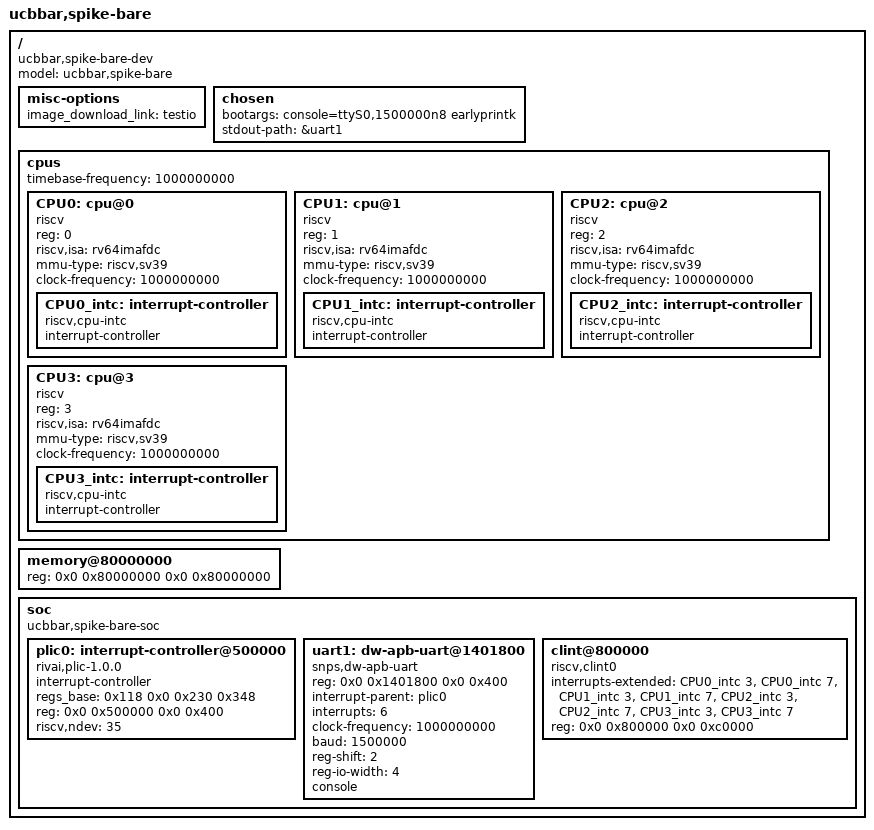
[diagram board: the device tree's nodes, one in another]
/dts-v1/;

/ {
  #address-cells = <2>;
  #size-cells = <2>;
  compatible = "ucbbar,spike-bare-dev";
  model = "ucbbar,spike-bare";
  misc-options {
       image_download_link = "testio";
  };
  chosen {
       bootargs = "console=ttyS0,1500000n8 earlyprintk";
       stdout-path = &uart1;
  };
  cpus {
    #address-cells = <1>;
    #size-cells = <0>;
    timebase-frequency = <1000000000>;
    CPU0: cpu@0 {
      device_type = "cpu";
      reg = <0>;
      status = "okay";
      compatible = "riscv";
      riscv,isa = "rv64imafdc";
      mmu-type = "riscv,sv39";
      clock-frequency = <1000000000>;
      CPU0_intc: interrupt-controller {
        #interrupt-cells = <1>;
        interrupt-controller;
        compatible = "riscv,cpu-intc";
      };
    };
    CPU1: cpu@1 {
      device_type = "cpu";
      reg = <1>;
      status = "okay";
      compatible = "riscv";
      riscv,isa = "rv64imafdc";
      mmu-type = "riscv,sv39";
      clock-frequency = <1000000000>;
      CPU1_intc: interrupt-controller {
        #interrupt-cells = <1>;
        interrupt-controller;
        compatible = "riscv,cpu-intc";
      };
    };
    CPU2: cpu@2 {
      device_type = "cpu";
      reg = <2>;
      status = "okay";
      compatible = "riscv";
      riscv,isa = "rv64imafdc";
      mmu-type = "riscv,sv39";
      clock-frequency = <1000000000>;
      CPU2_intc: interrupt-controller {
        #interrupt-cells = <1>;
        interrupt-controller;
        compatible = "riscv,cpu-intc";
      };
    };
    CPU3: cpu@3 {
      device_type = "cpu";
      reg = <3>;
      status = "okay";
      compatible = "riscv";
      riscv,isa = "rv64imafdc";
      mmu-type = "riscv,sv39";
      clock-frequency = <1000000000>;
      CPU3_intc: interrupt-controller {
        #interrupt-cells = <1>;
        interrupt-controller;
        compatible = "riscv,cpu-intc";
      };
    };
  };
  memory@80000000 {
    device_type = "memory";
    reg = <0x0 0x80000000 0x0 0x80000000>;
  };
  soc {
    #address-cells = <2>;
    #size-cells = <2>;
    compatible = "ucbbar,spike-bare-soc", "simple-bus";
    ranges;
    plic0: interrupt-controller@500000 {
      #interrupt-cells = <1>;
      compatible = "rivai,plic-1.0.0";
      interrupt-controller;
      regs_base = <0x118 0x0 0x230 0x348>;
      reg = <0x0 0x500000 0x0 0x400>;
      riscv,ndev = <35>;
    };
    uart1: dw-apb-uart@1401800 {
      compatible = "snps,dw-apb-uart";
      reg = <0x0 0x1401800 0x0 0x400>;
      interrupt-parent = <&plic0>;
      interrupts = <6>;
      clock-frequency = <1000000000>;
      baud = <1500000>;
      reg-shift = <2>;
      reg-io-width = <4>;
      console;
    };
    clint@800000 {
      compatible = "riscv,clint0";
      interrupts-extended = <&CPU0_intc 3 &CPU0_intc 7 &CPU1_intc 3 &CPU1_intc 7 &CPU2_intc 3 &CPU2_intc 7 &CPU3_intc 3 &CPU3_intc 7 >;
      reg = <0x0 0x800000 0x0 0xc0000>;
    };
  };
};
